# nrf54h20_engb_application register map
Vendor: Nordic Semiconductor; Series: nRF54h; File version: 1
CPU: CM33 r0p4, little endian, MPU, FPU, 3 interrupt priority bits, 480 interrupts, 8 SAU regions
Registers are 32-bit, read-write, reset 0x0 unless marked. A register's access mark holds for its fields unless they carry their own. Offsets are from the block's base; [hi:lo] are bit positions; lines under a group give offsets from that group; {n}, {i} and the like mark numbered series.

## GLOBAL_FICR_NS — Factory Information Configuration Registers
Base 0x0FFFE000
0x0C BLE group — Unspecified
  0x00 ADDRTYPE ro reset 0xFFFFFFFF — Device address type.
    [0] TYPE
      0=Public address; 1=Random address
  {0x4+4j} ADDR[{j}] (j=0..1) ro reset 0xFFFFFFFF — Description collection: 48 bit device address.
    [31:0] ADDR — Device address [n].
  {0xC+4j} ER[{j}] (j=0..3) ro reset 0xFFFFFFFF — Description collection: Encryption Root.
    [31:0] ER — Encryption root word [n].
  {0x1C+4j} IR[{j}] (j=0..3) ro reset 0xFFFFFFFF — Description collection: Identity Root.
    [31:0] IR — Identity root word [n].
0x40 NFC group — Unspecified
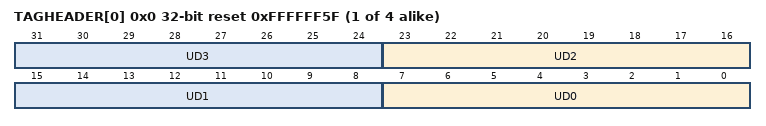
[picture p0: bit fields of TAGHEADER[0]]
  {0x0+4j} TAGHEADER[{j}] (j=0..3) ro reset 0xFFFFFF5F — Description collection: Default header for NFC Tag.
    [8n+7:8n] UD{n} (n=0..3) — Unique identifier byte {n}
0x50 INFO group — Device info
  0x00 CONFIGID ro reset 0xFFFFFFFF — Configuration identifier
    [15:0] HWID — Identification number for the HW
  0x04 PART ro reset 0xFFFFFFFF — Part code
    [31:0] PART
      0xFFFFFFFF=Unspecified
  0x08 VARIANT ro reset 0xFFFFFFFF — Part Variant, Hardware version and Production configuration
    [31:0] VARIANT — Part Variant, Hardware version and Production configuration, encoded as ASCII
      0xFFFFFFFF=Unspecified
  0x0C PACKAGE ro reset 0xFFFFFFFF — Package option
    [31:0] PACKAGE
      0xFFFFFFFF=Unspecified
  0x10 RAM ro reset 0xFFFFFFFF — RAM variant
    [31:0] RAM
      0xFFFFFFFF=Unspecified
  0x14 MRAM ro reset 0xFFFFFFFF — MRAM variant
    [31:0] MRAM
      0xFFFFFFFF=Unspecified
  0x18 CODEPAGESIZE ro reset 0x1000 — Code memory page size in bytes
    [31:0] CODEPAGESIZE
      0xFFFFFFFF=Unspecified
  0x1C CODESIZE ro reset 0x100 — Code memory size
    [31:0] CODESIZE — Code memory size in number of pages
      0xFFFFFFFF=Unspecified
  0x20 DEVICETYPE ro
    [31:0] DEVICETYPE
      0=Die (Device is an physical DIE); 0xFFFFFFFF=FPGA (Device is an FPGA)
0x100 TRIM group — Unspecified
  0x288 GLOBAL group — Unspecified
    0x00 SAADC group — Unspecified
      {0x0+4l} CAL[{l}] (l=0..2) ro reset 0xFFFFFFFF — Description collection: Trim value for GLOBAL.SAADC.CAL
        [31:0] VALUE — Trim value
      0x0C CALREF ro reset 0xFFFFFFFF — Trim value for GLOBAL.SAADC.CALREF
        [31:0] VALUE — Trim value
      {0x10+4l} LINCALCOEFF[{l}] (l=0..5) ro reset 0xFFFFFFFF — Description collection: Trim value for GLOBAL.SAADC.TRIM.LINCALCOEFF
        [31:0] VALUE — Trim value
    0x2C NFCT group — Unspecified
      0x00 BIASCFG ro reset 0xFFFFFFFF — Trim value for NFCT.BIASCFG
        [31:0] VALUE — Trim value
    0x30 CANPLL group — Unspecified
      0x00 TRIM group — Unspecified
        0x00 CTUNE ro reset 0xFFFFFFFF — Trim value for GLOBAL.CANPLL.TRIM.CTUNE
          [31:0] VALUE — Trim value
    0x38 COMP group — Unspecified
      0x00 REFTRIM ro reset 0xFFFFFFFF — Trim value for GLOBAL.COMP.REFTRIM
        [31:0] VALUE — Trim value
  0x2C8 APPLICATION group — Unspecified
    0x00 HSFLL group — Unspecified
      0x00 TRIM group — Unspecified
        0x00 VSUP ro reset 0xFFFFFFFF — Trim value for APPLICATION.HSFLL.TRIM.VSUP
          [31:0] VALUE — Trim value
        {0x4+4m} COARSE[{m}] (m=0..5) ro reset 0xFFFFFFFF — Description collection: Trim value for APPLICATION.HSFLL.TRIM.COARSE
          [31:0] VALUE — Trim value
        {0x1C+4m} FINE[{m}] (m=0..5) ro reset 0xFFFFFFFF — Description collection: Trim value for APPLICATION.HSFLL.TRIM.FINE
          [31:0] VALUE — Trim value
        0x34 TCOEF ro reset 0xFFFFFFFF — Trim value for APPLICATION.HSFLL.TRIM.TCOEF
          [31:0] VALUE — Trim value
    0x38 MEMCONF group — Unspecified
      {0x0+4l} BLOCKTYPE[{l}] (l=0..3) group — Unspecified
        0x00 TRIM ro reset 0xFFFFFFFF — Description cluster: Trim value for APPLICATION.MEMCONF.BLOCKTYPE[n].TRIM
          [31:0] VALUE — Trim value
  0x310 RADIOCORE group — Unspecified
    0x00 HSFLL group — Unspecified
      0x00 TRIM group — Unspecified
        0x00 VSUP ro reset 0xFFFFFFFF — Trim value for RADIOCORE.HSFLL.TRIM.VSUP
          [31:0] VALUE — Trim value
        {0x4+4m} COARSE[{m}] (m=0..5) ro reset 0xFFFFFFFF — Description collection: Trim value for RADIOCORE.HSFLL.TRIM.COARSE
          [31:0] VALUE — Trim value
        {0x1C+4m} FINE[{m}] (m=0..5) ro reset 0xFFFFFFFF — Description collection: Trim value for RADIOCORE.HSFLL.TRIM.FINE
          [31:0] VALUE — Trim value
        0x34 TCOEF ro reset 0xFFFFFFFF — Trim value for RADIOCORE.HSFLL.TRIM.TCOEF
          [31:0] VALUE — Trim value
    0x38 MEMCONF group — Unspecified
      {0x0+4l} BLOCKTYPE[{l}] (l=0..3) group — Unspecified
        0x00 TRIM ro reset 0xFFFFFFFF — Description cluster: Trim value for RADIOCORE.MEMCONF.BLOCKTYPE[n].TRIM
          [31:0] VALUE — Trim value

## Notices in the file
Copyright (c) 2010 - 2024, Nordic Semiconductor ASA All rights reserved.
SPDX-License-Identifier: BSD-3-Clause
Redistribution and use in source and binary forms, with or without
modification, are permitted provided that the following conditions are met:
1. Redistributions of source code must retain the above copyright notice, this
list of conditions and the following disclaimer.
2. Redistributions in binary form must reproduce the above copyright
notice, this list of conditions and the following disclaimer in the
documentation and/or other materials provided with the distribution.
3. Neither the name of Nordic Semiconductor ASA nor the names of its
contributors may be used to endorse or promote products derived from this
software without specific prior written permission.
THIS SOFTWARE IS PROVIDED BY THE COPYRIGHT HOLDERS AND CONTRIBUTORS "AS IS"
AND ANY EXPRESS OR IMPLIED WARRANTIES, INCLUDING, BUT NOT LIMITED TO, THE
IMPLIED WARRANTIES OF MERCHANTABILITY, AND FITNESS FOR A PARTICULAR PURPOSE
ARE DISCLAIMED. IN NO EVENT SHALL NORDIC SEMICONDUCTOR ASA OR CONTRIBUTORS BE
LIABLE FOR ANY DIRECT, INDIRECT, INCIDENTAL, SPECIAL, EXEMPLARY, OR
CONSEQUENTIAL DAMAGES (INCLUDING, BUT NOT LIMITED TO, PROCUREMENT OF
SUBSTITUTE GOODS OR SERVICES; LOSS OF USE, DATA, OR PROFITS; OR BUSINESS
INTERRUPTION) HOWEVER CAUSED AND ON ANY THEORY OF LIABILITY, WHETHER IN
CONTRACT, STRICT LIABILITY, OR TORT (INCLUDING NEGLIGENCE OR OTHERWISE)
ARISING IN ANY WAY OUT OF THE USE OF THIS SOFTWARE, EVEN IF ADVISED OF THE
POSSIBILITY OF SUCH DAMAGE.
